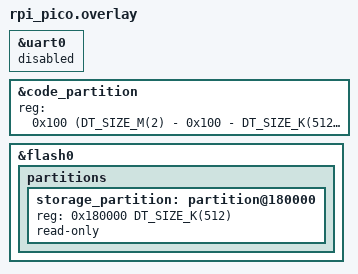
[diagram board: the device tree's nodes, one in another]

&uart0 { status = "disabled"; };

&code_partition {
    reg = <0x100 (DT_SIZE_M(2) - 0x100 - DT_SIZE_K(512))>;
};

&flash0 {
    partitions {
        storage_partition: partition@180000 {
            reg = <0x180000 DT_SIZE_K(512)>;
            read-only;
        };
    };
};
